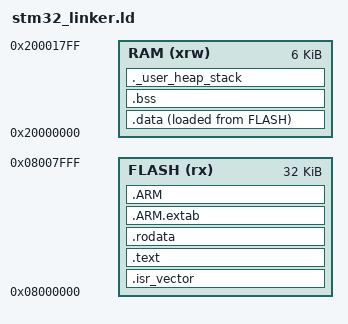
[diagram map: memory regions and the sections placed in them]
/* Entry point */
ENTRY(Reset_Handler)

/* Memory areas for STM32C011J6M6 */
MEMORY
{
  FLASH (rx)      : ORIGIN = 0x08000000, LENGTH = 32K   /* 32KB of Flash */
  RAM (xrw)       : ORIGIN = 0x20000000, LENGTH = 6K    /* 6KB of RAM */
}

/* Stack and Heap */
_estack = ORIGIN(RAM) + LENGTH(RAM);
_Min_Heap_Size = 0x100;   /* required amount of heap */
_Min_Stack_Size = 0x200;  /* required amount of stack */

/* Sections */
SECTIONS
{
  .isr_vector :
  {
    . = ALIGN(4);
    KEEP(*(.isr_vector))
    . = ALIGN(4);
  } >FLASH

  .text :
  {
    . = ALIGN(4);
    *(.text)           /* .text sections (code) */
    *(.text*)          /* .text* sections (code) */
    *(.glue_7)         /* glue arm to thumb code */
    *(.glue_7t)        /* glue thumb to arm code */
    *(.eh_frame)
    
    KEEP (*(.init))
    KEEP (*(.fini))
    
    . = ALIGN(4);
    _etext = .;        /* define a global symbols at end of code */
  } >FLASH

  /* Read-only data section */
  .rodata :
  {
    . = ALIGN(4);
    *(.rodata)         /* .rodata sections (constants, strings, etc.) */
    *(.rodata*)        /* .rodata* sections (constants, strings, etc.) */
    . = ALIGN(4);
  } >FLASH

  /* Used for dynamic memory allocation by "alloca" */
  .ARM.extab   : { *(.ARM.extab* .gnu.linkonce.armextab.*) } >FLASH
  .ARM : {
    __exidx_start = .;
    *(.ARM.exidx*)
    __exidx_end = .;
  } >FLASH

  /* Data section - moved from FLASH to RAM during startup */
  _sidata = LOADADDR(.data);
  
  .data :
  {
    . = ALIGN(4);
    _sdata = .;        /* create a global symbol at data start */
    *(.data)           /* .data sections */
    *(.data*)          /* .data* sections */
    
    . = ALIGN(4);
    _edata = .;        /* define a global symbol at data end */
  } >RAM AT> FLASH
  
  /* Uninitialized data section */
  . = ALIGN(4);
  .bss :
  {
    _sbss = .;         /* define a global symbol at bss start */
    __bss_start__ = _sbss;
    *(.bss)
    *(.bss*)
    *(COMMON)
    
    . = ALIGN(4);
    _ebss = .;         /* define a global symbol at bss end */
    __bss_end__ = _ebss;
  } >RAM
  
  /* User_heap_stack section, used to check that there is enough RAM left */
  ._user_heap_stack :
  {
    . = ALIGN(8);
    PROVIDE ( end = . );
    PROVIDE ( _end = . );
    . = . + _Min_Heap_Size;
    . = . + _Min_Stack_Size;
    . = ALIGN(8);
  } >RAM
  
  /* Remove standard libraries unwanted sections */
  /DISCARD/ :
  {
    libc.a ( * )
    libm.a ( * )
    libgcc.a ( * )
  }
}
